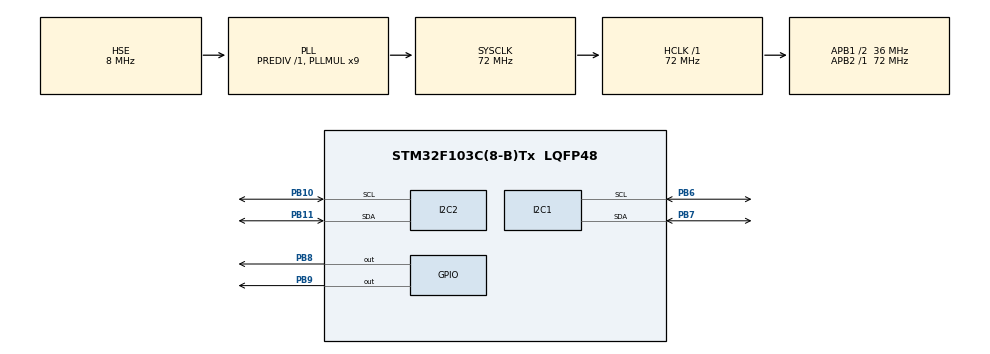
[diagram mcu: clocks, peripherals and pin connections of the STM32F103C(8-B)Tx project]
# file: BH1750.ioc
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Mcu.Family=STM32F1
Mcu.Name=STM32F103C(8-B)Tx
Mcu.Package=LQFP48
NVIC.PriorityGroup=NVIC_PRIORITYGROUP_4
PA13.Mode=Serial_Wire
PA13.Signal=SYS_JTMS-SWDIO
PA14.Mode=Serial_Wire
PA14.Signal=SYS_JTCK-SWCLK
PB10.Mode=I2C
PB10.Signal=I2C2_SCL
PB11.Mode=I2C
PB11.Signal=I2C2_SDA
PB6.Mode=I2C
PB6.Signal=I2C1_SCL
PB7.Mode=I2C
PB7.Signal=I2C1_SDA
PB8.Signal=GPIO_Output
PB9.Signal=GPIO_Output
PD0-OSC_IN.Mode=HSE-External-Oscillator
PD0-OSC_IN.Signal=RCC_OSC_IN
PD1-OSC_OUT.Mode=HSE-External-Oscillator
PD1-OSC_OUT.Signal=RCC_OSC_OUT
ProjectManager.HeapSize=0x200
ProjectManager.StackSize=0x400
ProjectManager.TargetToolchain=MDK-ARM V5
RCC.AHBFreq_Value=72000000
RCC.APB1CLKDivider=RCC_HCLK_DIV2
RCC.APB1Freq_Value=36000000
RCC.APB1TimFreq_Value=72000000
RCC.APB2Freq_Value=72000000
RCC.APB2TimFreq_Value=72000000
RCC.HCLKFreq_Value=72000000
RCC.HSIState=RCC_HSI_ON
RCC.PLLMUL=RCC_PLL_MUL9
RCC.PLLSourceVirtual=RCC_PLLSOURCE_HSE
RCC.SYSCLKFreq_VALUE=72000000
RCC.SYSCLKSource=RCC_SYSCLKSOURCE_PLLCLK
RCC.USBFreq_Value=72000000
TIM4.Period=71
VP_TIM4_VS_ClockSourceINT.Mode=Internal
board=BH1750

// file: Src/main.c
/**
  ******************************************************************************
  * File Name          : main.c
  * Description        : Main program body
  ******************************************************************************
  *
  * COPYRIGHT(c) 2018 STMicroelectronics
  *
  * Redistribution and use in source and binary forms, with or without modification,
  * are permitted provided that the following conditions are met:
  *   1. Redistributions of source code must retain the above copyright notice,
  *      this list of conditions and the following disclaimer.
  *   2. Redistributions in binary form must reproduce the above copyright notice,
  *      this list of conditions and the following disclaimer in the documentation
  *      and/or other materials provided with the distribution.
  *   3. Neither the name of STMicroelectronics nor the names of its contributors
  *      may be used to endorse or promote products derived from this software
  *      without specific prior written permission.
  *
  * THIS SOFTWARE IS PROVIDED BY THE COPYRIGHT HOLDERS AND CONTRIBUTORS "AS IS"
  * AND ANY EXPRESS OR IMPLIED WARRANTIES, INCLUDING, BUT NOT LIMITED TO, THE
  * IMPLIED WARRANTIES OF MERCHANTABILITY AND FITNESS FOR A PARTICULAR PURPOSE ARE
  * DISCLAIMED. IN NO EVENT SHALL THE COPYRIGHT HOLDER OR CONTRIBUTORS BE LIABLE
  * FOR ANY DIRECT, INDIRECT, INCIDENTAL, SPECIAL, EXEMPLARY, OR CONSEQUENTIAL
  * DAMAGES (INCLUDING, BUT NOT LIMITED TO, PROCUREMENT OF SUBSTITUTE GOODS OR
  * SERVICES; LOSS OF USE, DATA, OR PROFITS; OR BUSINESS INTERRUPTION) HOWEVER
  * CAUSED AND ON ANY THEORY OF LIABILITY, WHETHER IN CONTRACT, STRICT LIABILITY,
  * OR TORT (INCLUDING NEGLIGENCE OR OTHERWISE) ARISING IN ANY WAY OUT OF THE USE
  * OF THIS SOFTWARE, EVEN IF ADVISED OF THE POSSIBILITY OF SUCH DAMAGE.
  *
  ******************************************************************************
  */
#include "main.h"
#include "stm32f1xx_hal.h"

/* USER CODE BEGIN Includes */
#include "bh1750.h"
/* USER CODE END Includes */

I2C_HandleTypeDef hi2c1;
I2C_HandleTypeDef hi2c2;

TIM_HandleTypeDef htim4;

/* USER CODE BEGIN PV */
/* Private variables ---------------------------------------------------------*/
float value_lux = 0;
/* USER CODE END PV */

void SystemClock_Config(void);
void Error_Handler(void);
static void MX_GPIO_Init(void);
static void MX_I2C1_Init(void);
static void MX_I2C2_Init(void);
static void MX_TIM4_Init(void);

/* USER CODE BEGIN PFP */
/* Private function prototypes -----------------------------------------------*/

/* USER CODE END PFP */

int main(void)
{

  /* MCU Configuration----------------------------------------------------------*/

  /* Reset of all peripherals, Initializes the Flash interface and the Systick. */
  HAL_Init();

  /* Configure the system clock */
  SystemClock_Config();

  /* Initialize all configured peripherals */
  MX_GPIO_Init();
  MX_I2C1_Init();
  MX_I2C2_Init();
  MX_TIM4_Init();

  /* USER CODE BEGIN 2 */
	BH1750_Init();
	BH1750_Start();
	HAL_Delay(500);
  /* USER CODE END 2 */

  /* Infinite loop */
  while (1)
  {

  /* USER CODE BEGIN //3 */
	value_lux = BH1750_Read();
	HAL_Delay(100);
  }
  /* USER CODE END 3 */

}

/** System Clock Configuration
*/
void SystemClock_Config(void)
{

  RCC_OscInitTypeDef RCC_OscInitStruct;
  RCC_ClkInitTypeDef RCC_ClkInitStruct;

    /**Initializes the CPU, AHB and APB busses clocks
    */
  RCC_OscInitStruct.OscillatorType = RCC_OSCILLATORTYPE_HSE;
  RCC_OscInitStruct.HSEState = RCC_HSE_ON;
  RCC_OscInitStruct.HSEPredivValue = RCC_HSE_PREDIV_DIV1;
  RCC_OscInitStruct.HSIState = RCC_HSI_ON;
  RCC_OscInitStruct.PLL.PLLState = RCC_PLL_ON;
  RCC_OscInitStruct.PLL.PLLSource = RCC_PLLSOURCE_HSE;
  RCC_OscInitStruct.PLL.PLLMUL = RCC_PLL_MUL9;
  if (HAL_RCC_OscConfig(&RCC_OscInitStruct) != HAL_OK)
  {
    Error_Handler();
  }

    /**Initializes the CPU, AHB and APB busses clocks
    */
  RCC_ClkInitStruct.ClockType = RCC_CLOCKTYPE_HCLK|RCC_CLOCKTYPE_SYSCLK
                              |RCC_CLOCKTYPE_PCLK1|RCC_CLOCKTYPE_PCLK2;
  RCC_ClkInitStruct.SYSCLKSource = RCC_SYSCLKSOURCE_PLLCLK;
  RCC_ClkInitStruct.AHBCLKDivider = RCC_SYSCLK_DIV1;
  RCC_ClkInitStruct.APB1CLKDivider = RCC_HCLK_DIV2;
  RCC_ClkInitStruct.APB2CLKDivider = RCC_HCLK_DIV1;

  if (HAL_RCC_ClockConfig(&RCC_ClkInitStruct, FLASH_LATENCY_2) != HAL_OK)
  {
    Error_Handler();
  }

    /**Configure the Systick interrupt time
    */
  HAL_SYSTICK_Config(HAL_RCC_GetHCLKFreq()/1000);

    /**Configure the Systick
    */
  HAL_SYSTICK_CLKSourceConfig(SYSTICK_CLKSOURCE_HCLK);

  /* SysTick_IRQn interrupt configuration */
  HAL_NVIC_SetPriority(SysTick_IRQn, 0, 0);
}

/* I2C1 init function */
static void MX_I2C1_Init(void)
{

  hi2c1.Instance = I2C1;
  hi2c1.Init.ClockSpeed = 100000;
  hi2c1.Init.DutyCycle = I2C_DUTYCYCLE_2;
  hi2c1.Init.OwnAddress1 = 0;
  hi2c1.Init.AddressingMode = I2C_ADDRESSINGMODE_7BIT;
  hi2c1.Init.DualAddressMode = I2C_DUALADDRESS_DISABLE;
  hi2c1.Init.OwnAddress2 = 0;
  hi2c1.Init.GeneralCallMode = I2C_GENERALCALL_DISABLE;
  hi2c1.Init.NoStretchMode = I2C_NOSTRETCH_DISABLE;
  if (HAL_I2C_Init(&hi2c1) != HAL_OK)
  {
    Error_Handler();
  }

}

/* I2C2 init function */
static void MX_I2C2_Init(void)
{

  hi2c2.Instance = I2C2;
  hi2c2.Init.ClockSpeed = 100000;
  hi2c2.Init.DutyCycle = I2C_DUTYCYCLE_2;
  hi2c2.Init.OwnAddress1 = 0;
  hi2c2.Init.AddressingMode = I2C_ADDRESSINGMODE_7BIT;
  hi2c2.Init.DualAddressMode = I2C_DUALADDRESS_DISABLE;
  hi2c2.Init.OwnAddress2 = 0;
  hi2c2.Init.GeneralCallMode = I2C_GENERALCALL_DISABLE;
  hi2c2.Init.NoStretchMode = I2C_NOSTRETCH_DISABLE;
  if (HAL_I2C_Init(&hi2c2) != HAL_OK)
  {
    Error_Handler();
  }

}

/* TIM4 init function */
static void MX_TIM4_Init(void)
{

  TIM_ClockConfigTypeDef sClockSourceConfig;
  TIM_MasterConfigTypeDef sMasterConfig;

  htim4.Instance = TIM4;
  htim4.Init.Prescaler = 0;
  htim4.Init.CounterMode = TIM_COUNTERMODE_UP;
  htim4.Init.Period = 71;
  htim4.Init.ClockDivision = TIM_CLOCKDIVISION_DIV1;
  if (HAL_TIM_Base_Init(&htim4) != HAL_OK)
  {
    Error_Handler();
  }

  sClockSourceConfig.ClockSource = TIM_CLOCKSOURCE_INTERNAL;
  if (HAL_TIM_ConfigClockSource(&htim4, &sClockSourceConfig) != HAL_OK)
  {
    Error_Handler();
  }

  sMasterConfig.MasterOutputTrigger = TIM_TRGO_RESET;
  sMasterConfig.MasterSlaveMode = TIM_MASTERSLAVEMODE_DISABLE;
  if (HAL_TIMEx_MasterConfigSynchronization(&htim4, &sMasterConfig) != HAL_OK)
  {
    Error_Handler();
  }

}

/** Configure pins as
        * Analog
        * Input
        * Output
        * EVENT_OUT
        * EXTI
*/
static void MX_GPIO_Init(void)
{

  GPIO_InitTypeDef GPIO_InitStruct;

  /* GPIO Ports Clock Enable */
  __HAL_RCC_GPIOD_CLK_ENABLE();
  __HAL_RCC_GPIOB_CLK_ENABLE();
  __HAL_RCC_GPIOA_CLK_ENABLE();

  /*Configure GPIO pin Output Level */
  HAL_GPIO_WritePin(GPIOB, GPIO_PIN_8|GPIO_PIN_9, GPIO_PIN_RESET);

  /*Configure GPIO pins : PB8 PB9 */
  GPIO_InitStruct.Pin = GPIO_PIN_8|GPIO_PIN_9;
  GPIO_InitStruct.Mode = GPIO_MODE_OUTPUT_PP;
  GPIO_InitStruct.Speed = GPIO_SPEED_FREQ_LOW;
  HAL_GPIO_Init(GPIOB, &GPIO_InitStruct);

}

void Error_Handler(void)
{
  while(1)
  {
  }
}

/************************ (C) COPYRIGHT STMicroelectronics *****END OF FILE****/
